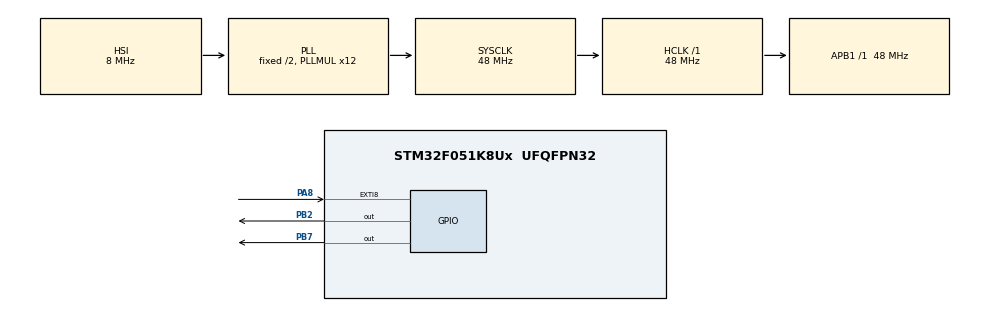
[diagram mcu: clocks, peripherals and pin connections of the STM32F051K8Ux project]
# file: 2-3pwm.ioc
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Mcu.Family=STM32F0
Mcu.Name=STM32F051K8Ux
Mcu.Package=UFQFPN32
NVIC.EXTI4_15_IRQn=true\:0\:0\:false\:false\:true\:true\:true\:true
NVIC.TIM6_DAC_IRQn=true\:1\:0\:true\:false\:true\:true\:true\:true
PA8.GPIO_ModeDefaultEXTI=GPIO_MODE_IT_RISING
PA8.Signal=GPXTI8
PB2.Signal=GPIO_Output
PB7.Signal=GPIO_Output
PF0-OSC_IN.Mode=HSE-External-Oscillator
PF0-OSC_IN.Signal=RCC_OSC_IN
PF1-OSC_OUT.Mode=HSE-External-Oscillator
PF1-OSC_OUT.Signal=RCC_OSC_OUT
ProjectManager.HeapSize=0x200
ProjectManager.StackSize=0x400
ProjectManager.TargetToolchain=MDK-ARM V5.32
RCC.AHBFreq_Value=48000000
RCC.APB1Freq_Value=48000000
RCC.APB1TimFreq_Value=48000000
RCC.HCLKFreq_Value=48000000
RCC.PLLMUL=RCC_PLL_MUL12
RCC.SYSCLKFreq_VALUE=48000000
RCC.SYSCLKSource=RCC_SYSCLKSOURCE_PLLCLK
TIM6.Period=9
TIM6.Prescaler=47
VP_TIM6_VS_ClockSourceINT.Mode=Enable_Timer
board=custom

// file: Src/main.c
/* USER CODE BEGIN Header */
/**
  ******************************************************************************
  * @file           : main.c
  * @brief          : Main program body
  ******************************************************************************
  * @attention
  *
  * Copyright (c) 2023 STMicroelectronics.
  * All rights reserved.
  *
  * This software is licensed under terms that can be found in the LICENSE file
  * in the root directory of this software component.
  * If no LICENSE file comes with this software, it is provided AS-IS.
  *
  ******************************************************************************
  */
/* USER CODE END Header */
#include "main.h"
#include "tim.h"
#include "gpio.h"

/* USER CODE BEGIN PTD */
volatile double timecount;
volatile uint16_t buttonflag=0;
volatile uint8_t flag=0;
/* USER CODE END PTD */

void SystemClock_Config(void);

/* USER CODE BEGIN 0 */
void HAL_GPIO_EXTI_Callback(uint16_t GPIO_Pin){
  if(flag==0){
    buttonflag++;
    if(buttonflag==2){
      flag=1;
    }
  }
  else if(flag==1){
    buttonflag--;
    if(buttonflag==0){
      flag=0;
    }
  }
}
void HAL_TIM_PeriodElapsedCallback(TIM_HandleTypeDef *htim){
  if(htim->Instance==TIM6){
    timecount--;
  }
}
void pwmf(double pwm){
  timecount=(1.0/pwm)/1e-5;
  __HAL_TIM_CLEAR_IT(&htim6,TIM_IT_UPDATE);
  HAL_TIM_Base_Start_IT(&htim6);
  while(timecount>0);
  HAL_TIM_Base_Stop_IT(&htim6);
}
/* USER CODE END 0 */

int main(void)
{

  /* MCU Configuration--------------------------------------------------------*/

  /* Reset of all peripherals, Initializes the Flash interface and the Systick. */
  HAL_Init();

  /* Configure the system clock */
  SystemClock_Config();

  /* Initialize all configured peripherals */
  MX_GPIO_Init();
  MX_TIM6_Init();

  /* Infinite loop */
  while (1)
  {

    /* USER CODE BEGIN 3 */
    if(buttonflag==0){
      pwmf(10.0);
      HAL_GPIO_TogglePin(GPIOB,GPIO_PIN_7);
      HAL_GPIO_TogglePin(GPIOB,GPIO_PIN_2);
    }
    if(buttonflag==1){
      pwmf(1000.0);
      HAL_GPIO_TogglePin(GPIOB,GPIO_PIN_7);
      HAL_GPIO_TogglePin(GPIOB,GPIO_PIN_2);
    }
    if(buttonflag==2){
      pwmf(100000.0);
      HAL_GPIO_TogglePin(GPIOB,GPIO_PIN_7);
      HAL_GPIO_TogglePin(GPIOB,GPIO_PIN_2);
    }
  }
  /* USER CODE END 3 */
}

void SystemClock_Config(void)
{
  RCC_OscInitTypeDef RCC_OscInitStruct = {0};
  RCC_ClkInitTypeDef RCC_ClkInitStruct = {0};

  /** Initializes the RCC Oscillators according to the specified parameters
  * in the RCC_OscInitTypeDef structure.
  */
  RCC_OscInitStruct.OscillatorType = RCC_OSCILLATORTYPE_HSI;
  RCC_OscInitStruct.HSIState = RCC_HSI_ON;
  RCC_OscInitStruct.HSICalibrationValue = RCC_HSICALIBRATION_DEFAULT;
  RCC_OscInitStruct.PLL.PLLState = RCC_PLL_ON;
  RCC_OscInitStruct.PLL.PLLSource = RCC_PLLSOURCE_HSI;
  RCC_OscInitStruct.PLL.PLLMUL = RCC_PLL_MUL12;
  RCC_OscInitStruct.PLL.PREDIV = RCC_PREDIV_DIV1;
  if (HAL_RCC_OscConfig(&RCC_OscInitStruct) != HAL_OK)
  {
    Error_Handler();
  }

  /** Initializes the CPU, AHB and APB buses clocks
  */
  RCC_ClkInitStruct.ClockType = RCC_CLOCKTYPE_HCLK|RCC_CLOCKTYPE_SYSCLK
                              |RCC_CLOCKTYPE_PCLK1;
  RCC_ClkInitStruct.SYSCLKSource = RCC_SYSCLKSOURCE_PLLCLK;
  RCC_ClkInitStruct.AHBCLKDivider = RCC_SYSCLK_DIV1;
  RCC_ClkInitStruct.APB1CLKDivider = RCC_HCLK_DIV1;

  if (HAL_RCC_ClockConfig(&RCC_ClkInitStruct, FLASH_LATENCY_1) != HAL_OK)
  {
    Error_Handler();
  }
}

void Error_Handler(void)
{
  __disable_irq();
  while (1)
  {
  }
}
